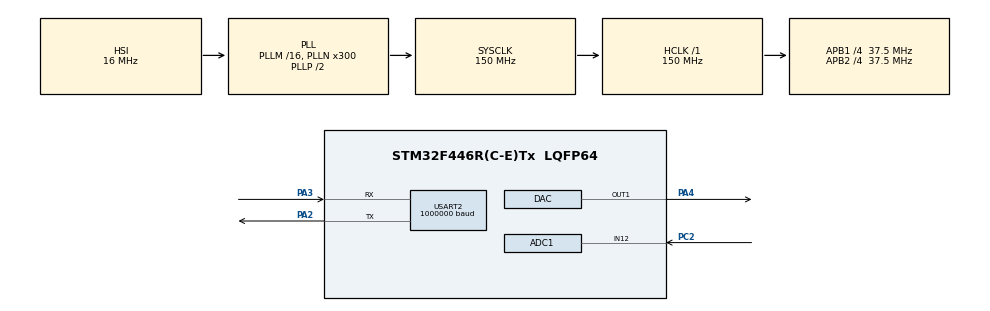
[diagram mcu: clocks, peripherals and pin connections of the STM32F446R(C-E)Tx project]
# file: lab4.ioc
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ADC1.Channel-4\#ChannelRegularConversion=ADC_CHANNEL_12
ADC1.NbrOfConversionFlag=1
ADC1.Rank-4\#ChannelRegularConversion=1
ADC1.SamplingTime-4\#ChannelRegularConversion=ADC_SAMPLETIME_3CYCLES
ADC1.master=1
Dma.ADC1.2.Direction=DMA_PERIPH_TO_MEMORY
Dma.ADC1.2.FIFOMode=DMA_FIFOMODE_DISABLE
Dma.ADC1.2.Instance=DMA2_Stream0
Dma.ADC1.2.MemDataAlignment=DMA_MDATAALIGN_HALFWORD
Dma.ADC1.2.MemInc=DMA_MINC_ENABLE
Dma.ADC1.2.Mode=DMA_NORMAL
Dma.ADC1.2.PeriphDataAlignment=DMA_PDATAALIGN_HALFWORD
Dma.ADC1.2.PeriphInc=DMA_PINC_DISABLE
Dma.ADC1.2.Priority=DMA_PRIORITY_LOW
Dma.Request0=TIM4_UP
Dma.Request1=USART2_RX
Dma.Request2=ADC1
Dma.TIM4_UP.0.Direction=DMA_PERIPH_TO_MEMORY
Dma.TIM4_UP.0.FIFOMode=DMA_FIFOMODE_DISABLE
Dma.TIM4_UP.0.Instance=DMA1_Stream6
Dma.TIM4_UP.0.MemDataAlignment=DMA_MDATAALIGN_HALFWORD
Dma.TIM4_UP.0.MemInc=DMA_MINC_ENABLE
Dma.TIM4_UP.0.Mode=DMA_NORMAL
Dma.TIM4_UP.0.PeriphDataAlignment=DMA_PDATAALIGN_HALFWORD
Dma.TIM4_UP.0.PeriphInc=DMA_PINC_DISABLE
Dma.TIM4_UP.0.Priority=DMA_PRIORITY_LOW
Dma.USART2_RX.1.Direction=DMA_PERIPH_TO_MEMORY
Dma.USART2_RX.1.FIFOMode=DMA_FIFOMODE_DISABLE
Dma.USART2_RX.1.Instance=DMA1_Stream5
Dma.USART2_RX.1.MemDataAlignment=DMA_MDATAALIGN_BYTE
Dma.USART2_RX.1.MemInc=DMA_MINC_ENABLE
Dma.USART2_RX.1.Mode=DMA_NORMAL
Dma.USART2_RX.1.PeriphDataAlignment=DMA_PDATAALIGN_BYTE
Dma.USART2_RX.1.PeriphInc=DMA_PINC_DISABLE
Dma.USART2_RX.1.Priority=DMA_PRIORITY_LOW
Mcu.Family=STM32F4
Mcu.Name=STM32F446R(C-E)Tx
Mcu.Package=LQFP64
NVIC.DMA1_Stream5_IRQn=true\:0\:0\:false\:false\:true\:false\:true\:true
NVIC.DMA1_Stream6_IRQn=true\:0\:0\:false\:false\:true\:false\:true\:true
NVIC.DMA2_Stream0_IRQn=true\:0\:0\:false\:false\:true\:false\:true\:true
NVIC.PriorityGroup=NVIC_PRIORITYGROUP_4
NVIC.TIM3_IRQn=true\:0\:0\:false\:false\:true\:true\:true\:true
NVIC.TIM4_IRQn=true\:0\:0\:false\:false\:true\:true\:true\:true
NVIC.USART2_IRQn=true\:0\:0\:false\:false\:true\:true\:true\:true
PA2.Mode=Asynchronous
PA2.Signal=USART2_TX
PA3.Mode=Asynchronous
PA3.Signal=USART2_RX
PA4.Signal=COMP_DAC1_group
PC2.Signal=ADCx_IN12
PH0-OSC_IN.Mode=HSE-External-Clock-Source
PH0-OSC_IN.Signal=RCC_OSC_IN
PH1-OSC_OUT.Mode=HSE-External-Clock-Source
PH1-OSC_OUT.Signal=RCC_OSC_OUT
ProjectManager.HeapSize=0x200
ProjectManager.StackSize=0x400
ProjectManager.TargetToolchain=STM32CubeIDE
RCC.AHBFreq_Value=150000000
RCC.APB1CLKDivider=RCC_HCLK_DIV4
RCC.APB1Freq_Value=37500000
RCC.APB1TimFreq_Value=75000000
RCC.APB2CLKDivider=RCC_HCLK_DIV4
RCC.APB2Freq_Value=37500000
RCC.APB2TimFreq_Value=75000000
RCC.CortexFreq_Value=150000000
RCC.HCLKFreq_Value=150000000
RCC.PLLN=300
RCC.SYSCLKFreq_VALUE=150000000
RCC.SYSCLKSource=RCC_SYSCLKSOURCE_PLLCLK
RCC.USBFreq_Value=150000000
RCC.VCOOutputFreq_Value=300000000
SH.ADCx_IN12.0=ADC1_IN12,IN12
SH.COMP_DAC1_group.0=DAC_OUT1,DAC_OUT1
TIM3.Period=9
TIM3.Prescaler=7499
TIM4.Period=74
TIM4.Prescaler=499
USART2.BaudRate=1000000
USART2.VirtualMode=VM_ASYNC
VP_TIM3_VS_ClockSourceINT.Mode=Internal
VP_TIM4_VS_ClockSourceINT.Mode=Internal
board=custom

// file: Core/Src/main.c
/* USER CODE BEGIN Header */
/**
  ******************************************************************************
  * @file           : main.c
  * @brief          : Main program body
  ******************************************************************************
  * @attention
  *
  * Copyright (c) 2024 STMicroelectronics.
  * All rights reserved.
  *
  * This software is licensed under terms that can be found in the LICENSE file
  * in the root directory of this software component.
  * If no LICENSE file comes with this software, it is provided AS-IS.
  *
  ******************************************************************************
  */
/* USER CODE END Header */
#include "main.h"

/* USER CODE BEGIN Includes */
#include "uart.h"
/* USER CODE END Includes */

 ADC_HandleTypeDef hadc1;
DMA_HandleTypeDef hdma_adc1;

DAC_HandleTypeDef hdac;

TIM_HandleTypeDef htim3;
TIM_HandleTypeDef htim4;
DMA_HandleTypeDef hdma_tim4_up;

UART_HandleTypeDef huart2;
DMA_HandleTypeDef hdma_usart2_rx;

void SystemClock_Config(void);
static void MX_GPIO_Init(void);
static void MX_DAC_Init(void);
static void MX_TIM4_Init(void);
static void MX_DMA_Init(void);
static void MX_ADC1_Init(void);
static void MX_USART2_UART_Init(void);
static void MX_TIM3_Init(void);

/* USER CODE BEGIN 0 */
extern uint8_t rx_buff[MAX_PACKET_LENGTH];
/* USER CODE END 0 */

int main(void)
{

  /* MCU Configuration--------------------------------------------------------*/

  /* Reset of all peripherals, Initializes the Flash interface and the Systick. */
  HAL_Init();

  /* Configure the system clock */
  SystemClock_Config();

  /* Initialize all configured peripherals */
  MX_GPIO_Init();
  MX_DAC_Init();
  MX_TIM4_Init();
  MX_DMA_Init();
  MX_ADC1_Init();
  MX_USART2_UART_Init();
  MX_TIM3_Init();

  /* Infinite loop */
  /* USER CODE BEGIN WHILE */
  HAL_TIM_Base_Start_IT(&htim3);
  HAL_TIM_Base_Start_IT(&htim4);
  HAL_DAC_Start(&hdac, DAC_CHANNEL_1);
  HAL_UART_Receive_IT(&huart2, rx_buff, PACKET_LENGTH);
  while (1)
  {
    /* USER CODE END WHILE */

  }
}

void SystemClock_Config(void)
{
  RCC_OscInitTypeDef RCC_OscInitStruct = {0};
  RCC_ClkInitTypeDef RCC_ClkInitStruct = {0};

  /** Configure the main internal regulator output voltage
  */
  __HAL_RCC_PWR_CLK_ENABLE();
  __HAL_PWR_VOLTAGESCALING_CONFIG(PWR_REGULATOR_VOLTAGE_SCALE1);

  /** Initializes the RCC Oscillators according to the specified parameters
  * in the RCC_OscInitTypeDef structure.
  */
  RCC_OscInitStruct.OscillatorType = RCC_OSCILLATORTYPE_HSI;
  RCC_OscInitStruct.HSIState = RCC_HSI_ON;
  RCC_OscInitStruct.HSICalibrationValue = RCC_HSICALIBRATION_DEFAULT;
  RCC_OscInitStruct.PLL.PLLState = RCC_PLL_ON;
  RCC_OscInitStruct.PLL.PLLSource = RCC_PLLSOURCE_HSI;
  RCC_OscInitStruct.PLL.PLLM = 16;
  RCC_OscInitStruct.PLL.PLLN = 300;
  RCC_OscInitStruct.PLL.PLLP = RCC_PLLP_DIV2;
  RCC_OscInitStruct.PLL.PLLQ = 2;
  RCC_OscInitStruct.PLL.PLLR = 2;
  if (HAL_RCC_OscConfig(&RCC_OscInitStruct) != HAL_OK)
  {
    Error_Handler();
  }

  /** Initializes the CPU, AHB and APB buses clocks
  */
  RCC_ClkInitStruct.ClockType = RCC_CLOCKTYPE_HCLK|RCC_CLOCKTYPE_SYSCLK
                              |RCC_CLOCKTYPE_PCLK1|RCC_CLOCKTYPE_PCLK2;
  RCC_ClkInitStruct.SYSCLKSource = RCC_SYSCLKSOURCE_PLLCLK;
  RCC_ClkInitStruct.AHBCLKDivider = RCC_SYSCLK_DIV1;
  RCC_ClkInitStruct.APB1CLKDivider = RCC_HCLK_DIV4;
  RCC_ClkInitStruct.APB2CLKDivider = RCC_HCLK_DIV4;

  if (HAL_RCC_ClockConfig(&RCC_ClkInitStruct, FLASH_LATENCY_4) != HAL_OK)
  {
    Error_Handler();
  }
}

static void MX_ADC1_Init(void)
{

  ADC_ChannelConfTypeDef sConfig = {0};

  /** Configure the global features of the ADC (Clock, Resolution, Data Alignment and number of conversion)
  */
  hadc1.Instance = ADC1;
  hadc1.Init.ClockPrescaler = ADC_CLOCK_SYNC_PCLK_DIV2;
  hadc1.Init.Resolution = ADC_RESOLUTION_12B;
  hadc1.Init.ScanConvMode = DISABLE;
  hadc1.Init.ContinuousConvMode = DISABLE;
  hadc1.Init.DiscontinuousConvMode = DISABLE;
  hadc1.Init.ExternalTrigConvEdge = ADC_EXTERNALTRIGCONVEDGE_NONE;
  hadc1.Init.ExternalTrigConv = ADC_SOFTWARE_START;
  hadc1.Init.DataAlign = ADC_DATAALIGN_RIGHT;
  hadc1.Init.NbrOfConversion = 1;
  hadc1.Init.DMAContinuousRequests = DISABLE;
  hadc1.Init.EOCSelection = ADC_EOC_SINGLE_CONV;
  if (HAL_ADC_Init(&hadc1) != HAL_OK)
  {
    Error_Handler();
  }

  /** Configure for the selected ADC regular channel its corresponding rank in the sequencer and its sample time.
  */
  sConfig.Channel = ADC_CHANNEL_12;
  sConfig.Rank = 1;
  sConfig.SamplingTime = ADC_SAMPLETIME_3CYCLES;
  if (HAL_ADC_ConfigChannel(&hadc1, &sConfig) != HAL_OK)
  {
    Error_Handler();
  }

}

static void MX_DAC_Init(void)
{

  DAC_ChannelConfTypeDef sConfig = {0};

  /** DAC Initialization
  */
  hdac.Instance = DAC;
  if (HAL_DAC_Init(&hdac) != HAL_OK)
  {
    Error_Handler();
  }

  /** DAC channel OUT1 config
  */
  sConfig.DAC_Trigger = DAC_TRIGGER_NONE;
  sConfig.DAC_OutputBuffer = DAC_OUTPUTBUFFER_ENABLE;
  if (HAL_DAC_ConfigChannel(&hdac, &sConfig, DAC_CHANNEL_1) != HAL_OK)
  {
    Error_Handler();
  }

}

static void MX_TIM3_Init(void)
{

  TIM_ClockConfigTypeDef sClockSourceConfig = {0};
  TIM_MasterConfigTypeDef sMasterConfig = {0};

  htim3.Instance = TIM3;
  htim3.Init.Prescaler = 7499;
  htim3.Init.CounterMode = TIM_COUNTERMODE_UP;
  htim3.Init.Period = 9;
  htim3.Init.ClockDivision = TIM_CLOCKDIVISION_DIV1;
  htim3.Init.AutoReloadPreload = TIM_AUTORELOAD_PRELOAD_DISABLE;
  if (HAL_TIM_Base_Init(&htim3) != HAL_OK)
  {
    Error_Handler();
  }
  sClockSourceConfig.ClockSource = TIM_CLOCKSOURCE_INTERNAL;
  if (HAL_TIM_ConfigClockSource(&htim3, &sClockSourceConfig) != HAL_OK)
  {
    Error_Handler();
  }
  sMasterConfig.MasterOutputTrigger = TIM_TRGO_RESET;
  sMasterConfig.MasterSlaveMode = TIM_MASTERSLAVEMODE_DISABLE;
  if (HAL_TIMEx_MasterConfigSynchronization(&htim3, &sMasterConfig) != HAL_OK)
  {
    Error_Handler();
  }

}

static void MX_TIM4_Init(void)
{

  TIM_ClockConfigTypeDef sClockSourceConfig = {0};
  TIM_MasterConfigTypeDef sMasterConfig = {0};

  htim4.Instance = TIM4;
  htim4.Init.Prescaler = 499;
  htim4.Init.CounterMode = TIM_COUNTERMODE_UP;
  htim4.Init.Period = 74;
  htim4.Init.ClockDivision = TIM_CLOCKDIVISION_DIV1;
  htim4.Init.AutoReloadPreload = TIM_AUTORELOAD_PRELOAD_DISABLE;
  if (HAL_TIM_Base_Init(&htim4) != HAL_OK)
  {
    Error_Handler();
  }
  sClockSourceConfig.ClockSource = TIM_CLOCKSOURCE_INTERNAL;
  if (HAL_TIM_ConfigClockSource(&htim4, &sClockSourceConfig) != HAL_OK)
  {
    Error_Handler();
  }
  sMasterConfig.MasterOutputTrigger = TIM_TRGO_RESET;
  sMasterConfig.MasterSlaveMode = TIM_MASTERSLAVEMODE_DISABLE;
  if (HAL_TIMEx_MasterConfigSynchronization(&htim4, &sMasterConfig) != HAL_OK)
  {
    Error_Handler();
  }

}

static void MX_USART2_UART_Init(void)
{

  huart2.Instance = USART2;
  huart2.Init.BaudRate = 1000000;
  huart2.Init.WordLength = UART_WORDLENGTH_8B;
  huart2.Init.StopBits = UART_STOPBITS_1;
  huart2.Init.Parity = UART_PARITY_NONE;
  huart2.Init.Mode = UART_MODE_TX_RX;
  huart2.Init.HwFlowCtl = UART_HWCONTROL_NONE;
  huart2.Init.OverSampling = UART_OVERSAMPLING_16;
  if (HAL_UART_Init(&huart2) != HAL_OK)
  {
    Error_Handler();
  }

}

static void MX_DMA_Init(void)
{

  /* DMA controller clock enable */
  __HAL_RCC_DMA1_CLK_ENABLE();
  __HAL_RCC_DMA2_CLK_ENABLE();

  /* DMA interrupt init */
  /* DMA1_Stream5_IRQn interrupt configuration */
  HAL_NVIC_SetPriority(DMA1_Stream5_IRQn, 0, 0);
  HAL_NVIC_EnableIRQ(DMA1_Stream5_IRQn);
  /* DMA1_Stream6_IRQn interrupt configuration */
  HAL_NVIC_SetPriority(DMA1_Stream6_IRQn, 0, 0);
  HAL_NVIC_EnableIRQ(DMA1_Stream6_IRQn);
  /* DMA2_Stream0_IRQn interrupt configuration */
  HAL_NVIC_SetPriority(DMA2_Stream0_IRQn, 0, 0);
  HAL_NVIC_EnableIRQ(DMA2_Stream0_IRQn);

}

static void MX_GPIO_Init(void)
{

  /* GPIO Ports Clock Enable */
  __HAL_RCC_GPIOH_CLK_ENABLE();
  __HAL_RCC_GPIOC_CLK_ENABLE();
  __HAL_RCC_GPIOA_CLK_ENABLE();

}

void Error_Handler(void)
{
  __disable_irq();
  while (1)
  {
  }
}
